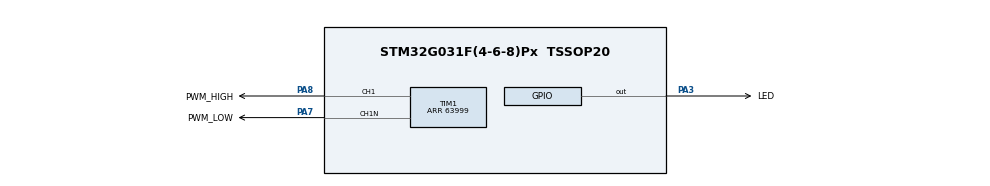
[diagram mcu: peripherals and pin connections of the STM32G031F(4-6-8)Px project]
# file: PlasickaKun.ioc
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Mcu.Family=STM32G0
Mcu.Name=STM32G031F(4-6-8)Px
Mcu.Package=TSSOP20
PA13.Mode=Serial_Wire
PA13.Signal=SYS_SWDIO
PA14-BOOT0.Mode=Serial_Wire
PA14-BOOT0.Signal=SYS_SWCLK
PA14-BOOT0__PA15.StandardMode=true
PA3.GPIO_Label=LED
PA3.Signal=GPIO_Output
PA7.GPIO_Speed=GPIO_SPEED_FREQ_HIGH
PA7.GPIO_Label=PWM_LOW
PA7.Mode=PWM Generation1 CH1 CH1N
PA7.Signal=TIM1_CH1N
PA8.GPIO_Speed=GPIO_SPEED_FREQ_HIGH
PA8.GPIO_Label=PWM_HIGH
PA8.Signal=S_TIM1_CH1
PB0__PB1__PB2__PA8.StandardMode=true
PB3__PB4__PB5__PB6.StandardMode=true
PB7__PB8.StandardMode=true
PC14-OSC32_IN\ (PC14)__PB9.StandardMode=true
ProjectManager.HeapSize=0x200
ProjectManager.StackSize=0x400
ProjectManager.TargetToolchain=CMake
RCC.ADCFreq_Value=64000000
RCC.AHBFreq_Value=64000000
RCC.CortexFreq_Value=64000000
RCC.EXTERNAL_CLOCK_VALUE=12288000
RCC.HCLKFreq_Value=64000000
RCC.HSE_VALUE=8000000
RCC.HSI_VALUE=16000000
RCC.LSE_VALUE=32768
RCC.SYSCLKFreq_VALUE=64000000
RCC.SYSCLKSource=RCC_SYSCLKSOURCE_PLLCLK
RCC.VCOOutputFreq_Value=128000000
SH.S_TIM1_CH1.0=TIM1_CH1,PWM Generation1 CH1 CH1N
TIM1.AutoReloadPreload=TIM_AUTORELOAD_PRELOAD_ENABLE
TIM1.Channel-PWM\ Generation1\ CH1\ CH1N=TIM_CHANNEL_1
TIM1.ClockDivision=TIM_CLOCKDIVISION_DIV2
TIM1.DeadTime=96
TIM1.OffStateIDLEMode=TIM_OSSI_ENABLE
TIM1.OffStateRunMode=TIM_OSSR_ENABLE
TIM1.Period=63999
TIM1.Pulse-PWM\ Generation1\ CH1\ CH1N=32000
VP_TIM1_VS_ClockSourceINT.Mode=Internal
board=custom

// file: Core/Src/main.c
/* USER CODE BEGIN Header */
/**
  ******************************************************************************
  * @file           : main.c
  * @brief          : Main program body
  ******************************************************************************
  * @attention
  *
  * Copyright (c) 2026 STMicroelectronics.
  * All rights reserved.
  *
  * This software is licensed under terms that can be found in the LICENSE file
  * in the root directory of this software component.
  * If no LICENSE file comes with this software, it is provided AS-IS.
  *
  ******************************************************************************
  */
/* USER CODE END Header */
#include "main.h"

/* USER CODE BEGIN Includes */
#include "stm32g0xx_it.h"
#include "stm32g0xx.h"
#include "stm32g0xx_ll_bus.h"
#include "stm32g0xx_ll_rcc.h"
#include "stm32g0xx_ll_system.h"
#include "stm32g0xx_ll_utils.h"

#include "ChirpGenerator.hpp"
#include "HBridgePwm.hpp"
#include "cfg.hpp"

/* USER CODE END Includes */

void SystemClock_Config(void);
static void MX_GPIO_Init(void);
static void MX_TIM1_Init(void);

/* USER CODE BEGIN 0 */

// Per-device (not per-boot) PRNG seed derived from the 96-bit factory
// unique ID, so different boards don't all sweep through an identical
// frequency sequence.
std::uint32_t ReadSeedFromUniqueId()
{
    const std::uint32_t* uid = reinterpret_cast<const std::uint32_t*>(UID_BASE);
    return uid[0] ^ uid[1] ^ uid[2] ^ 0xA53C9F17U;
}
/* USER CODE END 0 */

int main(void)
{

  /* MCU Configuration--------------------------------------------------------*/

  /* Reset of all peripherals, Initializes the Flash interface and the Systick. */
  LL_APB2_GRP1_EnableClock(LL_APB2_GRP1_PERIPH_SYSCFG);
  LL_APB1_GRP1_EnableClock(LL_APB1_GRP1_PERIPH_PWR);

  /* SysTick_IRQn interrupt configuration */
  NVIC_SetPriority(SysTick_IRQn, 3);

  /* Configure the system clock */
  SystemClock_Config();

  /* USER CODE BEGIN SysInit */
  // LL_Init1msTick configures the counter; enable its interrupt explicitly.
  LL_SYSTICK_EnableIT();

  /* USER CODE END SysInit */

  /* Initialize all configured peripherals */
  MX_GPIO_Init();
  MX_TIM1_Init();
  /* USER CODE BEGIN 2 */

  HBridgePwm hbridge(config::FREQUENCY_MIN_HZ);
  ChirpGenerator chirp(hbridge, ReadSeedFromUniqueId());
  chirp.Begin(GetTickMs());
  uint32_t lastLedTick = GetTickMs();
  /* USER CODE END 2 */

  /* Infinite loop */
  while (1)
  {

    /* USER CODE BEGIN 3 */
    const uint32_t nowMs = GetTickMs();
    chirp.Update(nowMs);

    // Blink with LED to see if it is running
    if ((nowMs - lastLedTick) >= 500U) {
      lastLedTick = nowMs;
      LL_GPIO_TogglePin(LED_GPIO_Port, LED_Pin);
    }
  }
  /* USER CODE END 3 */
}

void SystemClock_Config(void)
{
  LL_FLASH_SetLatency(LL_FLASH_LATENCY_2);
  while(LL_FLASH_GetLatency() != LL_FLASH_LATENCY_2)
  {
  }

  /* HSI configuration and activation */
  LL_RCC_HSI_Enable();
  while(LL_RCC_HSI_IsReady() != 1)
  {
  }

  /* Main PLL configuration and activation */
  LL_RCC_PLL_ConfigDomain_SYS(LL_RCC_PLLSOURCE_HSI, LL_RCC_PLLM_DIV_1, 8, LL_RCC_PLLR_DIV_2);
  LL_RCC_PLL_Enable();
  LL_RCC_PLL_EnableDomain_SYS();
  while(LL_RCC_PLL_IsReady() != 1)
  {
  }

  /* Set AHB prescaler*/
  LL_RCC_SetAHBPrescaler(LL_RCC_SYSCLK_DIV_1);

  /* Sysclk activation on the main PLL */
  LL_RCC_SetSysClkSource(LL_RCC_SYS_CLKSOURCE_PLL);
  while(LL_RCC_GetSysClkSource() != LL_RCC_SYS_CLKSOURCE_STATUS_PLL)
  {
  }

  /* Set APB1 prescaler*/
  LL_RCC_SetAPB1Prescaler(LL_RCC_APB1_DIV_1);

  LL_Init1msTick(64000000);

  /* Update CMSIS variable (which can be updated also through SystemCoreClockUpdate function) */
  LL_SetSystemCoreClock(64000000);
}

static void MX_TIM1_Init(void)
{

  LL_TIM_InitTypeDef TIM_InitStruct = {0};
  LL_TIM_OC_InitTypeDef TIM_OC_InitStruct = {0};
  LL_TIM_BDTR_InitTypeDef TIM_BDTRInitStruct = {0};

  LL_GPIO_InitTypeDef GPIO_InitStruct = {0};

  LL_RCC_SetTIMClockSource(LL_RCC_TIM1_CLKSOURCE_PCLK1);

  /* Peripheral clock enable */
  LL_APB2_GRP1_EnableClock(LL_APB2_GRP1_PERIPH_TIM1);

  TIM_InitStruct.Prescaler = 0;
  TIM_InitStruct.CounterMode = LL_TIM_COUNTERMODE_UP;
  TIM_InitStruct.Autoreload = 63999;
  TIM_InitStruct.ClockDivision = LL_TIM_CLOCKDIVISION_DIV2;
  TIM_InitStruct.RepetitionCounter = 0;
  LL_TIM_Init(TIM1, &TIM_InitStruct);
  LL_TIM_EnableARRPreload(TIM1);
  LL_TIM_SetClockSource(TIM1, LL_TIM_CLOCKSOURCE_INTERNAL);
  LL_TIM_OC_EnablePreload(TIM1, LL_TIM_CHANNEL_CH1);
  TIM_OC_InitStruct.OCMode = LL_TIM_OCMODE_PWM1;
  TIM_OC_InitStruct.OCState = LL_TIM_OCSTATE_DISABLE;
  TIM_OC_InitStruct.OCNState = LL_TIM_OCSTATE_DISABLE;
  TIM_OC_InitStruct.CompareValue = 32000;
  TIM_OC_InitStruct.OCPolarity = LL_TIM_OCPOLARITY_HIGH;
  TIM_OC_InitStruct.OCNPolarity = LL_TIM_OCPOLARITY_HIGH;
  TIM_OC_InitStruct.OCIdleState = LL_TIM_OCIDLESTATE_LOW;
  TIM_OC_InitStruct.OCNIdleState = LL_TIM_OCIDLESTATE_LOW;
  LL_TIM_OC_Init(TIM1, LL_TIM_CHANNEL_CH1, &TIM_OC_InitStruct);
  LL_TIM_OC_DisableFast(TIM1, LL_TIM_CHANNEL_CH1);
  LL_TIM_SetTriggerOutput(TIM1, LL_TIM_TRGO_RESET);
  LL_TIM_SetTriggerOutput2(TIM1, LL_TIM_TRGO2_RESET);
  LL_TIM_DisableMasterSlaveMode(TIM1);
  TIM_BDTRInitStruct.OSSRState = LL_TIM_OSSR_ENABLE;
  TIM_BDTRInitStruct.OSSIState = LL_TIM_OSSI_ENABLE;
  TIM_BDTRInitStruct.LockLevel = LL_TIM_LOCKLEVEL_OFF;
  TIM_BDTRInitStruct.DeadTime = 96;
  TIM_BDTRInitStruct.BreakState = LL_TIM_BREAK_DISABLE;
  TIM_BDTRInitStruct.BreakPolarity = LL_TIM_BREAK_POLARITY_HIGH;
  TIM_BDTRInitStruct.BreakFilter = LL_TIM_BREAK_FILTER_FDIV1;
  TIM_BDTRInitStruct.BreakAFMode = LL_TIM_BREAK_AFMODE_INPUT;
  TIM_BDTRInitStruct.Break2State = LL_TIM_BREAK2_DISABLE;
  TIM_BDTRInitStruct.Break2Polarity = LL_TIM_BREAK2_POLARITY_HIGH;
  TIM_BDTRInitStruct.Break2Filter = LL_TIM_BREAK2_FILTER_FDIV1;
  TIM_BDTRInitStruct.Break2AFMode = LL_TIM_BREAK_AFMODE_INPUT;
  TIM_BDTRInitStruct.AutomaticOutput = LL_TIM_AUTOMATICOUTPUT_DISABLE;
  LL_TIM_BDTR_Init(TIM1, &TIM_BDTRInitStruct);
  LL_IOP_GRP1_EnableClock(LL_IOP_GRP1_PERIPH_GPIOA);
  /**TIM1 GPIO Configuration
  PA7   ------> TIM1_CH1N
  PA8   ------> TIM1_CH1
  */
  GPIO_InitStruct.Pin = PWM_LOW_Pin;
  GPIO_InitStruct.Mode = LL_GPIO_MODE_ALTERNATE;
  GPIO_InitStruct.Speed = LL_GPIO_SPEED_FREQ_HIGH;
  GPIO_InitStruct.OutputType = LL_GPIO_OUTPUT_PUSHPULL;
  GPIO_InitStruct.Pull = LL_GPIO_PULL_NO;
  GPIO_InitStruct.Alternate = LL_GPIO_AF_2;
  LL_GPIO_Init(PWM_LOW_GPIO_Port, &GPIO_InitStruct);

  GPIO_InitStruct.Pin = PWM_HIGH_Pin;
  GPIO_InitStruct.Mode = LL_GPIO_MODE_ALTERNATE;
  GPIO_InitStruct.Speed = LL_GPIO_SPEED_FREQ_HIGH;
  GPIO_InitStruct.OutputType = LL_GPIO_OUTPUT_PUSHPULL;
  GPIO_InitStruct.Pull = LL_GPIO_PULL_NO;
  GPIO_InitStruct.Alternate = LL_GPIO_AF_2;
  LL_GPIO_Init(PWM_HIGH_GPIO_Port, &GPIO_InitStruct);

}

static void MX_GPIO_Init(void)
{
  LL_GPIO_InitTypeDef GPIO_InitStruct = {0};

  /* GPIO Ports Clock Enable */
  LL_IOP_GRP1_EnableClock(LL_IOP_GRP1_PERIPH_GPIOA);

  /**/
  LL_GPIO_ResetOutputPin(LED_GPIO_Port, LED_Pin);

  /**/
  GPIO_InitStruct.Pin = LED_Pin;
  GPIO_InitStruct.Mode = LL_GPIO_MODE_OUTPUT;
  GPIO_InitStruct.Speed = LL_GPIO_SPEED_FREQ_LOW;
  GPIO_InitStruct.OutputType = LL_GPIO_OUTPUT_PUSHPULL;
  GPIO_InitStruct.Pull = LL_GPIO_PULL_NO;
  LL_GPIO_Init(LED_GPIO_Port, &GPIO_InitStruct);

}

void Error_Handler(void)
{
  __disable_irq();
  while (1)
  {
  }
}
